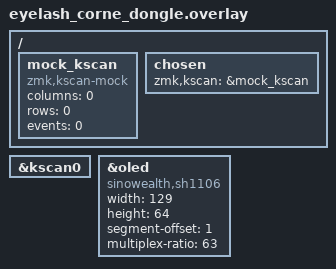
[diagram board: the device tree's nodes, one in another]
/*
*
* Copyright (c) 2021 Darryl deHaan
* SPDX-License-Identifier: MIT
*
*/

#include "eyelash_corne.dtsi"

/ {
    mock_kscan: mock_kscan {
        compatible = "zmk,kscan-mock";
        columns = <0>;
        rows = <0>;
        events = <0>;
    };

    chosen {
        zmk,kscan = &mock_kscan;
    };
};

&kscan0 {
    /delete-property/ wakeup-source;
    /delete-property/ diode-direction;
};

&oled {
    compatible = "sinowealth,sh1106";
    width = <129>;
    height = <64>;
    segment-offset = <1>;
    multiplex-ratio = <63>;
    /delete-property/ com-sequential;
};
